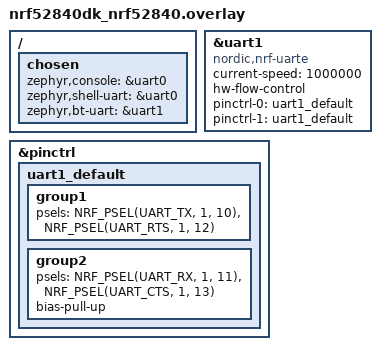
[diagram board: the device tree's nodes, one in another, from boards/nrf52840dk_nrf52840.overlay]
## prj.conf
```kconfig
CONFIG_BT=y
CONFIG_LOG=n
CONFIG_BT_PERIPHERAL=y

# Just in case auto-adv-restart doesn't work
CONFIG_BT_MAX_CONN=2

CONFIG_BT_DEVICE_NAME="🪘🐱"
CONFIG_BT_DEVICE_APPEARANCE=2501

CONFIG_INPUT=y
CONFIG_INPUT_MODE_SYNCHRONOUS=y

CONFIG_THREAD_MONITOR=y
CONFIG_THREAD_NAME=y

CONFIG_BT_GAP_AUTO_UPDATE_CONN_PARAMS=y
CONFIG_BT_GAP_PERIPHERAL_PREF_PARAMS=y
CONFIG_BT_PERIPHERAL_PREF_MIN_INT=6
CONFIG_BT_PERIPHERAL_PREF_MAX_INT=10

CONFIG_INPUT=y
CONFIG_INPUT_MODE_SYNCHRONOUS=y
```

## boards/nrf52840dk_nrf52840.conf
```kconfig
CONFIG_BT_CTLR=n
CONFIG_BT_SPI=y

# Need to set this to override the default stack size
CONFIG_BT_HCI_TX_STACK_SIZE_WITH_PROMPT=y

# Increase this as necessary
CONFIG_BT_HCI_TX_STACK_SIZE=1024
```

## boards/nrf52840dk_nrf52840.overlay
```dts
/ {
	chosen {
		zephyr,console = &uart0;
		zephyr,shell-uart = &uart0;
		zephyr,bt-uart = &uart1;
	};
};

&uart1 {
	compatible = "nordic,nrf-uarte";
	current-speed = <1000000>;
	status = "okay";
	hw-flow-control;
	pinctrl-0 = <&uart1_default>;
	pinctrl-1 = <&uart1_default>;
};

&pinctrl {
	uart1_default: uart1_default {
		group1 {
			psels = <NRF_PSEL(UART_TX, 1, 10)>,
				<NRF_PSEL(UART_RTS, 1, 12)>;
		};
		group2 {
			psels = <NRF_PSEL(UART_RX, 1, 11)>,
				<NRF_PSEL(UART_CTS, 1, 13)>;
			bias-pull-up;
		};
	};
};
```

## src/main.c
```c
#include <zephyr/bluetooth/bluetooth.h>
#include <zephyr/bluetooth/gatt.h>
#include <zephyr/bluetooth/conn.h>
#include <zephyr/input/input.h>

#include <zephyr/logging/log.h>
LOG_MODULE_REGISTER(main, 4);


static volatile bool subscribed;

static void ccc_changed(const struct bt_gatt_attr *attr, uint16_t value)
{
	/* assume we only get it for the `custom_gatt_service` */
	if (value != 0) {
		subscribed = 1;
	} else {
		subscribed = 0;
	}
}

#define custom_service_uuid                                                                          \
	BT_UUID_DECLARE_128(BT_UUID_128_ENCODE(0xf0debc9a, 0x7856, 0x3412, 0x7856, 0x341278563412))
#define custom_characteristic_uuid                                                                   \
	BT_UUID_DECLARE_128(BT_UUID_128_ENCODE(0xf2debc9a, 0x7856, 0x3412, 0x7856, 0x341278563412))

BT_GATT_SERVICE_DEFINE(custom_gatt_service, BT_GATT_PRIMARY_SERVICE(custom_service_uuid),
		       BT_GATT_CHARACTERISTIC(custom_characteristic_uuid,
					      (BT_GATT_CHRC_READ | BT_GATT_CHRC_NOTIFY),
					      BT_GATT_PERM_READ, NULL, NULL,
					      NULL),
		       BT_GATT_CCC(ccc_changed, BT_GATT_PERM_READ | BT_GATT_PERM_WRITE),);

static const struct bt_data ad[] = {
	BT_DATA_BYTES(BT_DATA_FLAGS, (BT_LE_AD_GENERAL | BT_LE_AD_NO_BREDR)),
	BT_DATA(BT_DATA_NAME_COMPLETE, CONFIG_BT_DEVICE_NAME, sizeof(CONFIG_BT_DEVICE_NAME) - 1),
};

static void connected(struct bt_conn *conn, uint8_t err)
{
	if (err) {
		printk("Connection failed (err 0x%02x)\n", err);
	} else {
		printk("Connected\n");
	}
}

static void disconnected(struct bt_conn *conn, uint8_t reason)
{
	printk("Disconnected (reason 0x%02x)\n", reason);
}

BT_CONN_CB_DEFINE(conn_callbacks) = {
	.connected = connected,
	.disconnected = disconnected,
};

#define BT_LE_ADV_CUSTOM BT_LE_ADV_PARAM(BT_LE_ADV_OPT_CONNECTABLE |	\
					 BT_LE_ADV_OPT_USE_IDENTITY,	\
					 BT_GAP_ADV_FAST_INT_MIN_2,	\
					 BT_GAP_ADV_FAST_INT_MAX_2, NULL)

static void send_data(uint8_t mask)
{
	const struct bt_gatt_attr *attr = &custom_gatt_service.attrs[2];

	if (!subscribed) {
		LOG_DBG("not subscribed");
		return;
	}

	int err = bt_gatt_notify(NULL, attr, &mask, 1);

	if (err) {
		LOG_DBG("Failed to notify: %d", err);
	}
}

static void set_clear(uint8_t *m, int index, int value)
{
	if (value) {
		*m |= BIT(index);
	} else {
		*m &= ~BIT(index);
	}
}

static void input_cb(struct input_event *evt)
{
	static uint8_t mask = 0;

	LOG_DBG("%s: sync %u type %u code 0x%x value %d", __func__,
		evt->sync, evt->type, evt->code, evt->value);

	if (evt->code == INPUT_KEY_0) {
		LOG_ERR("left %d", evt->value);
		set_clear(&mask, 0, evt->value);
	}

	if (evt->code == INPUT_KEY_1) {
		LOG_ERR("right %d", evt->value);
		set_clear(&mask, 1, evt->value);
	}

	send_data(mask);
}

/* Invoke callback for all input devices */
INPUT_CALLBACK_DEFINE(NULL, input_cb);

int main(void)
{
	int err;

	err = bt_enable(NULL);
	if (err) {
		printk("Bluetooth init failed (err %d)\n", err);
		return 0;
	}

	printk("Bluetooth initialized\n");

	printk("Starting Legacy Advertising (connectable and scannable)\n");
	err = bt_le_adv_start(BT_LE_ADV_CUSTOM, ad, ARRAY_SIZE(ad), NULL, 0);
	if (err) {
		printk("Advertising failed to start (err %d)\n", err);
		return 0;
	}

	printk("Advertising successfully started\n");

	return 0;
}
```
